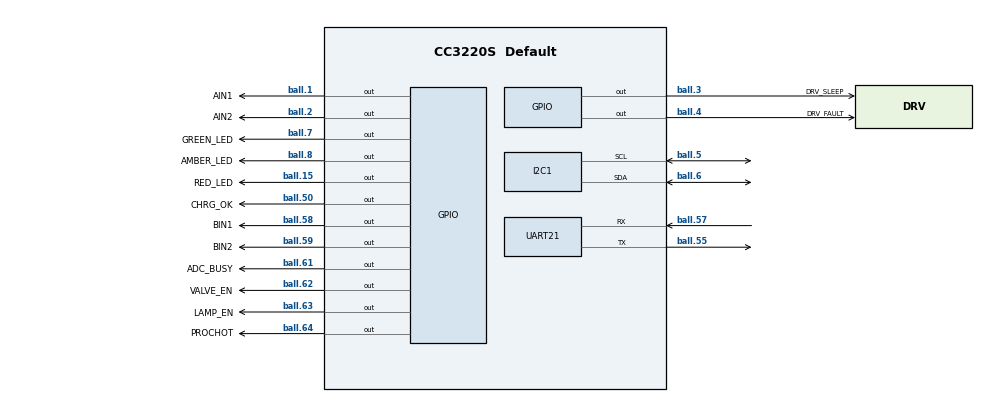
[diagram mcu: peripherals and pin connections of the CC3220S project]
/**
 * These arguments were used when this file was generated. They will be automatically applied on subsequent loads
 * via the GUI or CLI. Run CLI with '--help' for additional information on how to override these arguments.
 * @cliArgs --device "CC3220S" --package "Default" --part "Default" --rtos "tirtos7" --product "simplelink_cc32xx_sdk@6.10.00.05"
 * @versions {"tool":"1.14.0+2667"}
 */
scripting.excludeFromBuild("ti_utils_runtime_model.gv");
scripting.excludeFromBuild("ti_utils_runtime_Makefile");

/**
 * Import the modules used in this configuration.
 */
const GPIO     = scripting.addModule("/ti/drivers/GPIO", {}, false);
const GPIO1    = GPIO.addInstance();
const GPIO2    = GPIO.addInstance();
const GPIO3    = GPIO.addInstance();
const GPIO4    = GPIO.addInstance();
const GPIO5    = GPIO.addInstance();
const GPIO6    = GPIO.addInstance();
const GPIO7    = GPIO.addInstance();
const GPIO8    = GPIO.addInstance();
const GPIO9    = GPIO.addInstance();
const GPIO10   = GPIO.addInstance();
const GPIO11   = GPIO.addInstance();
const GPIO12   = GPIO.addInstance();
const GPIO13   = GPIO.addInstance();
const GPIO14   = GPIO.addInstance();
const I2C      = scripting.addModule("/ti/drivers/I2C", {}, false);
const I2C1     = I2C.addInstance();
const UART2    = scripting.addModule("/ti/drivers/UART2", {}, false);
const UART21   = UART2.addInstance();
const Settings = scripting.addModule("/ti/posix/tirtos/Settings");
const BIOS     = scripting.addModule("/ti/sysbios/BIOS");

/**
 * Write custom configuration values to the imported modules.
 */
GPIO1.$name           = "AIN1";
GPIO1.mode            = "Output";
GPIO1.gpioPin.$assign = "ball.1";

GPIO2.$name           = "AIN2";
GPIO2.mode            = "Output";
GPIO2.gpioPin.$assign = "ball.2";

GPIO3.$name           = "DRV_SLEEP";
GPIO3.mode            = "Output";
GPIO3.gpioPin.$assign = "ball.3";

GPIO4.$name           = "DRV_FAULT";
GPIO4.gpioPin.$assign = "ball.4";

GPIO5.$name           = "GREEN_LED";
GPIO5.mode            = "Output";
GPIO5.gpioPin.$assign = "ball.7";

GPIO6.$name           = "AMBER_LED";
GPIO6.mode            = "Output";
GPIO6.gpioPin.$assign = "ball.8";

GPIO7.$name           = "RED_LED";
GPIO7.mode            = "Output";
GPIO7.gpioPin.$assign = "ball.15";

GPIO8.$name           = "CHRG_OK";
GPIO8.gpioPin.$assign = "ball.50";

GPIO9.$name           = "BIN1";
GPIO9.mode            = "Output";
GPIO9.gpioPin.$assign = "ball.58";

GPIO10.$name           = "BIN2";
GPIO10.mode            = "Output";
GPIO10.gpioPin.$assign = "ball.59";

GPIO11.$name           = "ADC_BUSY";
GPIO11.gpioPin.$assign = "ball.61";

GPIO12.$name           = "VALVE_EN";
GPIO12.mode            = "Output";
GPIO12.gpioPin.$assign = "ball.62";

GPIO13.$name           = "LAMP_EN";
GPIO13.mode            = "Output";
GPIO13.gpioPin.$assign = "ball.63";

GPIO14.$name           = "PROCHOT";
GPIO14.gpioPin.$assign = "ball.64";

I2C1.$name              = "MyI2C1";
I2C1.i2c.$assign        = "I2C0";
I2C1.i2c.sdaPin.$assign = "ball.6";
I2C1.i2c.sclPin.$assign = "ball.5";

const Power          = scripting.addModule("/ti/drivers/Power", {}, false);
Power.parkPins.$name = "ti_drivers_power_PowerCC32XXPins0";

UART21.$name              = "MyUART1";
UART21.uart.$assign       = "UART0";
UART21.uart.txPin.$assign = "ball.55";
UART21.uart.rxPin.$assign = "ball.57";

/**
 * These are the reserved peripherals and settings in this configuration
 */
const iJTAG1       = scripting.addPeripheral("JTAG");
iJTAG1.$name       = "MyJTAG1";
iJTAG1.$assign     = "JTAG0";
iJTAG1.TDI.$assign = "ball.16";
iJTAG1.TDO.$assign = "ball.17";
iJTAG1.TCK.$assign = "ball.19";
iJTAG1.TMS.$assign = "ball.20";

/**
 * Pinmux solution for unlocked pins/peripherals. This ensures that minor changes to the automatic solver in a future
 * version of the tool will not impact the pinmux you originally saw.  These lines can be completely deleted in order to
 * re-solve from scratch.
 */
UART21.uart.txDmaChannel.$suggestSolution = "UDMA_CH9";
UART21.uart.rxDmaChannel.$suggestSolution = "UDMA_CH8";
